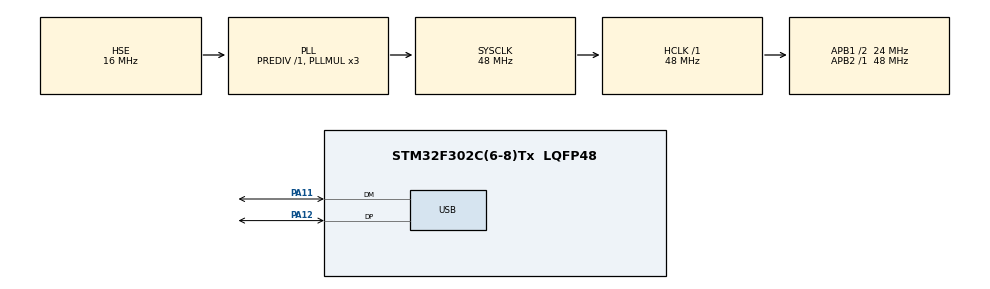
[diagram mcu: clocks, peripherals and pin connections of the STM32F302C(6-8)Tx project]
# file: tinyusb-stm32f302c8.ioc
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Mcu.Family=STM32F3
Mcu.Name=STM32F302C(6-8)Tx
Mcu.Package=LQFP48
NVIC.PriorityGroup=NVIC_PRIORITYGROUP_4
NVIC.USB_HP_CAN_TX_IRQn=true\:0\:0\:false\:false\:true\:true\:true\:true
NVIC.USB_LP_CAN_RX0_IRQn=true\:0\:0\:false\:false\:true\:true\:true\:true
PA11.Mode=Device
PA11.Signal=USB_DM
PA12.Mode=Device
PA12.Signal=USB_DP
PA13.Mode=Serial_Wire
PA13.Signal=SYS_JTMS-SWDIO
PA14.Mode=Serial_Wire
PA14.Signal=SYS_JTCK-SWCLK
PF0-OSC_IN.Mode=HSE-External-Oscillator
PF0-OSC_IN.Signal=RCC_OSC_IN
PF1-OSC_OUT.Mode=HSE-External-Oscillator
PF1-OSC_OUT.Signal=RCC_OSC_OUT
ProjectManager.HeapSize=0x200
ProjectManager.StackSize=0x400
ProjectManager.TargetToolchain=STM32CubeIDE
RCC.AHBFreq_Value=48000000
RCC.APB1CLKDivider=RCC_HCLK_DIV2
RCC.APB1Freq_Value=24000000
RCC.APB1TimFreq_Value=48000000
RCC.APB2Freq_Value=48000000
RCC.APB2TimFreq_Value=48000000
RCC.CortexFreq_Value=48000000
RCC.HCLKFreq_Value=48000000
RCC.HSE_VALUE=16000000
RCC.HSI_VALUE=8000000
RCC.LSE_VALUE=32768
RCC.PLLMUL=RCC_PLL_MUL3
RCC.SYSCLKFreq_VALUE=48000000
RCC.SYSCLKSourceVirtual=RCC_SYSCLKSOURCE_PLLCLK
RCC.USBFreq_Value=48000000
board=custom

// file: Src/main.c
/* USER CODE BEGIN Header */
/**
 ******************************************************************************
 * @file           : main.c
 * @brief          : Main program body
 ******************************************************************************
 * @attention
 *
 * Copyright (c) 2024 STMicroelectronics.
 * All rights reserved.
 *
 * This software is licensed under terms that can be found in the LICENSE file
 * in the root directory of this software component.
 * If no LICENSE file comes with this software, it is provided AS-IS.
 *
 ******************************************************************************
 */
/* USER CODE END Header */
#include "main.h"

PCD_HandleTypeDef hpcd_USB_FS;

void SystemClock_Config(void);
static void MX_GPIO_Init(void);
static void MX_USB_PCD_Init(void);
/* USER CODE BEGIN PFP */
void renumerate_usb(void);

/* USER CODE END PFP */

/* USER CODE BEGIN 0 */
#define CHUNK_SIZE 64
// Write string constants which have a size over one block (64)
void safe_cdc_write_const(char message[], uint32_t message_size)
{
  char *chunk = message;
  for (size_t i = 0; i + CHUNK_SIZE < message_size; i += CHUNK_SIZE)
  {
    tud_cdc_write(chunk, CHUNK_SIZE);
    tud_cdc_write_flush();
    chunk += CHUNK_SIZE;
  }
  tud_cdc_write(chunk, strlen(chunk));
  tud_cdc_write_flush();
}
/* USER CODE END 0 */

int main(void)
{

  /* MCU Configuration--------------------------------------------------------*/

  /* Reset of all peripherals, Initializes the Flash interface and the Systick. */
  HAL_Init();

  /* Configure the system clock */
  SystemClock_Config();

  /* Initialize all configured peripherals */
  MX_GPIO_Init();
  MX_USB_PCD_Init();
  /* USER CODE BEGIN 2 */
  renumerate_usb(); // MUST BE PLACED BEFORE tusb_init();
  tusb_init();

  void cdc_task(void);
  /* USER CODE END 2 */

  /* Infinite loop */
  /* USER CODE BEGIN WHILE */

// NOTE: This help message is not displayed when using the VScode serial monitor.
#define HELP_MSG "Echo test. Any text sent over serial should be echoed back immediately.\r\n"
  while (1)
  {
    tud_task();
    if (tud_cdc_connected())
    {
      safe_cdc_write_const(HELP_MSG, sizeof(HELP_MSG));
      break;
    }
  }

  while (1)
  {
    tud_task();
    cdc_task();
    /* USER CODE END WHILE */

  }
}

//--------------------------------------------------------------------+
// USB CDC
//--------------------------------------------------------------------+
void cdc_task(void)
{
  uint8_t itf;

  // connected() check for DTR bit
  // Most but not all terminal client set this when making connection
  // if ( tud_cdc_n_connected(itf) )
  // {
#define ECHO_TEXT "ECHO=\""
#define END_TEXT "\"\n"
  while (tud_cdc_available())
  {
    uint8_t buf[64];

    uint32_t count = tud_cdc_read(buf, sizeof(buf));

    tud_cdc_write(buf, count);
    tud_cdc_write_flush();
  }
  // }
}

void renumerate_usb(void)
{
  /*
   * https://stm32world.com/wiki/STM32_USB_Device_Renumeration
   * Force host to re-enumerate device
   */
  GPIO_InitTypeDef GPIO_InitStruct = {0};                // All zeroed out
  GPIO_InitStruct.Pin = GPIO_PIN_12;                     // Hardcoding this - PA12 is D+
  GPIO_InitStruct.Mode = GPIO_MODE_OUTPUT_PP;            // Push-pull mode
  GPIO_InitStruct.Pull = GPIO_PULLDOWN;                  // Resetting so pull low
  GPIO_InitStruct.Speed = GPIO_SPEED_HIGH;               // Really shouldn't matter in this case
  HAL_GPIO_Init(GPIOA, &GPIO_InitStruct);                // Initialize with above settings
  HAL_GPIO_WritePin(GPIOA, GPIO_PIN_12, GPIO_PIN_RESET); // Yank low
  HAL_Delay(50);                                         // Enough time for host to disconnect device
  HAL_GPIO_WritePin(GPIOA, GPIO_PIN_12, GPIO_PIN_SET);   // Back high - so host will enumerate
  HAL_GPIO_DeInit(GPIOA, GPIO_PIN_12);                   // Deinitialize the pin
}

void SystemClock_Config(void)
{
  RCC_OscInitTypeDef RCC_OscInitStruct = {0};
  RCC_ClkInitTypeDef RCC_ClkInitStruct = {0};
  RCC_PeriphCLKInitTypeDef PeriphClkInit = {0};

  /** Initializes the RCC Oscillators according to the specified parameters
   * in the RCC_OscInitTypeDef structure.
   */
  RCC_OscInitStruct.OscillatorType = RCC_OSCILLATORTYPE_HSE;
  RCC_OscInitStruct.HSEState = RCC_HSE_ON;
  RCC_OscInitStruct.HSEPredivValue = RCC_HSE_PREDIV_DIV1;
  RCC_OscInitStruct.HSIState = RCC_HSI_ON;
  RCC_OscInitStruct.PLL.PLLState = RCC_PLL_ON;
  RCC_OscInitStruct.PLL.PLLSource = RCC_PLLSOURCE_HSE;
  RCC_OscInitStruct.PLL.PLLMUL = RCC_PLL_MUL3;
  if (HAL_RCC_OscConfig(&RCC_OscInitStruct) != HAL_OK)
  {
    Error_Handler();
  }

  /** Initializes the CPU, AHB and APB buses clocks
   */
  RCC_ClkInitStruct.ClockType = RCC_CLOCKTYPE_HCLK | RCC_CLOCKTYPE_SYSCLK | RCC_CLOCKTYPE_PCLK1 | RCC_CLOCKTYPE_PCLK2;
  RCC_ClkInitStruct.SYSCLKSource = RCC_SYSCLKSOURCE_PLLCLK;
  RCC_ClkInitStruct.AHBCLKDivider = RCC_SYSCLK_DIV1;
  RCC_ClkInitStruct.APB1CLKDivider = RCC_HCLK_DIV2;
  RCC_ClkInitStruct.APB2CLKDivider = RCC_HCLK_DIV1;

  if (HAL_RCC_ClockConfig(&RCC_ClkInitStruct, FLASH_LATENCY_1) != HAL_OK)
  {
    Error_Handler();
  }
  PeriphClkInit.PeriphClockSelection = RCC_PERIPHCLK_USB;
  PeriphClkInit.USBClockSelection = RCC_USBCLKSOURCE_PLL;
  if (HAL_RCCEx_PeriphCLKConfig(&PeriphClkInit) != HAL_OK)
  {
    Error_Handler();
  }
}

static void MX_USB_PCD_Init(void)
{

  hpcd_USB_FS.Instance = USB;
  hpcd_USB_FS.Init.dev_endpoints = 8;
  hpcd_USB_FS.Init.speed = PCD_SPEED_FULL;
  hpcd_USB_FS.Init.phy_itface = PCD_PHY_EMBEDDED;
  hpcd_USB_FS.Init.low_power_enable = DISABLE;
  hpcd_USB_FS.Init.battery_charging_enable = DISABLE;
  if (HAL_PCD_Init(&hpcd_USB_FS) != HAL_OK)
  {
    Error_Handler();
  }
}

static void MX_GPIO_Init(void)
{

  /* GPIO Ports Clock Enable */
  __HAL_RCC_GPIOF_CLK_ENABLE();
  __HAL_RCC_GPIOA_CLK_ENABLE();

}

void Error_Handler(void)
{
  __disable_irq();
  while (1)
  {
  }
}
